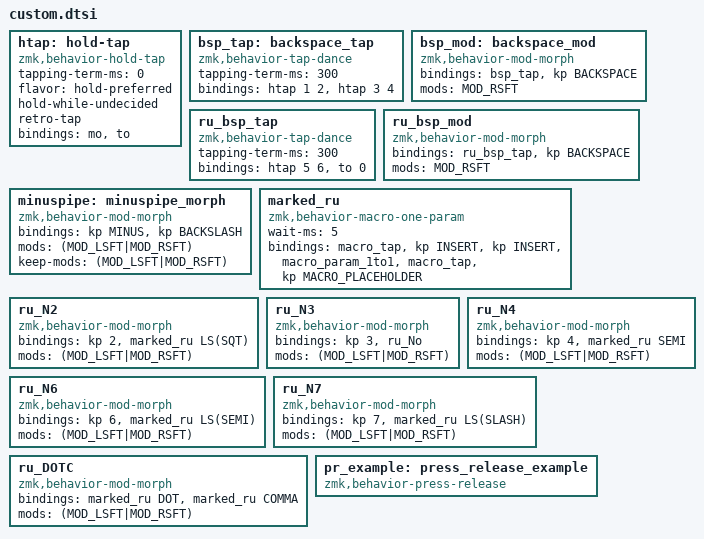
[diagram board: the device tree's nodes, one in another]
htap: hold-tap {
	compatible = "zmk,behavior-hold-tap";
	#binding-cells = <2>;
	tapping-term-ms = <0>;
	flavor = "hold-preferred";
	hold-while-undecided;
	retro-tap;
	bindings = <&mo>, <&to>;
};

bsp_tap: backspace_tap {
	compatible = "zmk,behavior-tap-dance";
	#binding-cells = <0>;
	tapping-term-ms = <300>;
	bindings = <&htap 1 2>, <&htap 3 4>;
};
bsp_mod: backspace_mod {
	compatible = "zmk,behavior-mod-morph";
	#binding-cells = <0>;
	bindings = <&bsp_tap>, <&kp BACKSPACE>;
	mods = <MOD_RSFT>;
};

ru_bsp_tap: ru_bsp_tap {
	compatible = "zmk,behavior-tap-dance";
	#binding-cells = <0>;
	tapping-term-ms = <300>;
	bindings = <&htap 5 6>, <&to 0>;
};
ru_bsp_mod: ru_bsp_mod {
	compatible = "zmk,behavior-mod-morph";
	#binding-cells = <0>;
	bindings = <&ru_bsp_tap>, <&kp BACKSPACE>;
	mods = <MOD_RSFT>;
};

minuspipe: minuspipe_morph {
	compatible = "zmk,behavior-mod-morph";
	#binding-cells = <0>;
	bindings = <&kp MINUS>, <&kp BACKSLASH>;
	mods = <(MOD_LSFT|MOD_RSFT)>;
	keep-mods = <(MOD_LSFT|MOD_RSFT)>;
};

marked_ru: marked_ru {
	compatible = "zmk,behavior-macro-one-param";
	#binding-cells = <1>;
	wait-ms = <5>;
	bindings =
		<&macro_tap &kp INSERT &kp INSERT>, \
		<&macro_param_1to1>,
		<&macro_tap &kp MACRO_PLACEHOLDER>;
};
ru_N2: ru_N2 {
	compatible = "zmk,behavior-mod-morph";
	#binding-cells = <0>;
	bindings = <&kp 2>, <&marked_ru LS(SQT)>;
	mods = <(MOD_LSFT|MOD_RSFT)>;
};
ru_N3: ru_N3 {
	compatible = "zmk,behavior-mod-morph";
	#binding-cells = <0>;
	bindings = <&kp 3>, <&ru_No>;
	mods = <(MOD_LSFT|MOD_RSFT)>;
};
ru_N4: ru_N4 {
	compatible = "zmk,behavior-mod-morph";
	#binding-cells = <0>;
	bindings = <&kp 4>, <&marked_ru SEMI>;
	mods = <(MOD_LSFT|MOD_RSFT)>;
};
ru_N6: ru_N6 {
	compatible = "zmk,behavior-mod-morph";
	#binding-cells = <0>;
	bindings = <&kp 6>, <&marked_ru LS(SEMI)>;
	mods = <(MOD_LSFT|MOD_RSFT)>;
};
ru_N7: ru_N7 {
	compatible = "zmk,behavior-mod-morph";
	#binding-cells = <0>;
	bindings = <&kp 7>, <&marked_ru LS(SLASH)>;
	mods = <(MOD_LSFT|MOD_RSFT)>;
};
ru_DOTC: ru_DOTC {
	compatible = "zmk,behavior-mod-morph";
	#binding-cells = <0>;
	bindings = <&marked_ru DOT>, <&marked_ru COMMA>;
	mods = <(MOD_LSFT|MOD_RSFT)>;
};

// Press-Release behavior example: sends A on press, B on release
pr_example: press_release_example {
	compatible = "zmk,behavior-press-release";
	#binding-cells = <2>;
};

